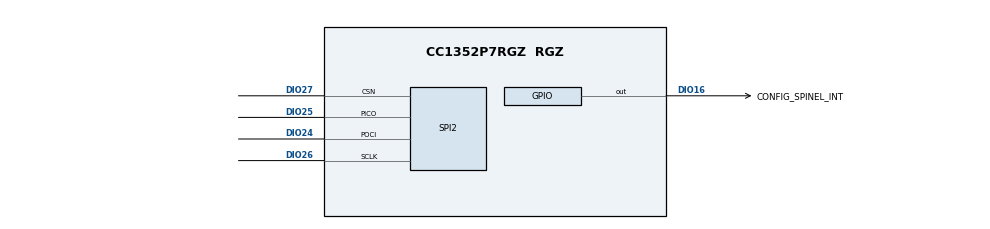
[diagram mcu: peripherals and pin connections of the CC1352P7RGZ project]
/*
 * Copyright (c) 2018, Texas Instruments Incorporated
 * All rights reserved.
 *
 * Redistribution and use in source and binary forms, with or without
 * modification, are permitted provided that the following conditions
 * are met:
 *
 * *  Redistributions of source code must retain the above copyright
 *    notice, this list of conditions and the following disclaimer.
 *
 * *  Redistributions in binary form must reproduce the above copyright
 *    notice, this list of conditions and the following disclaimer in the
 *    documentation and/or other materials provided with the distribution.
 *
 * *  Neither the name of Texas Instruments Incorporated nor the names of
 *    its contributors may be used to endorse or promote products derived
 *    from this software without specific prior written permission.
 *
 * THIS SOFTWARE IS PROVIDED BY THE COPYRIGHT HOLDERS AND CONTRIBUTORS "AS IS"
 * AND ANY EXPRESS OR IMPLIED WARRANTIES, INCLUDING, BUT NOT LIMITED TO,
 * THE IMPLIED WARRANTIES OF MERCHANTABILITY AND FITNESS FOR A PARTICULAR
 * PURPOSE ARE DISCLAIMED. IN NO EVENT SHALL THE COPYRIGHT OWNER OR
 * CONTRIBUTORS BE LIABLE FOR ANY DIRECT, INDIRECT, INCIDENTAL, SPECIAL,
 * EXEMPLARY, OR CONSEQUENTIAL DAMAGES (INCLUDING, BUT NOT LIMITED TO,
 * PROCUREMENT OF SUBSTITUTE GOODS OR SERVICES; LOSS OF USE, DATA, OR PROFITS;
 * OR BUSINESS INTERRUPTION) HOWEVER CAUSED AND ON ANY THEORY OF LIABILITY,
 * WHETHER IN CONTRACT, STRICT LIABILITY, OR TORT (INCLUDING NEGLIGENCE OR
 * OTHERWISE) ARISING IN ANY WAY OUT OF THE USE OF THIS SOFTWARE,
 * EVEN IF ADVISED OF THE POSSIBILITY OF SUCH DAMAGE.
 */

/*
 *  cli_ftd.syscfg
 */

/**
 * @cliArgs --board "/ti/boards/LP_CC1352P7_4" --device "CC1352P7RGZ" --part "Default" --package "RGZ" --rtos "freertos" --product "simplelink_cc13xx_cc26xx_sdk@7.40.00.77"
 * @versions {"tool":"1.24.1+4189"}
 */

/* Modules */
var AESECB    = scripting.addModule("/ti/drivers/AESECB");
var DMA       = scripting.addModule("/ti/drivers/DMA");
var Device    = scripting.addModule("/ti/devices/CCFG");
var ECDH      = scripting.addModule("/ti/drivers/ECDH");
var ECDSA     = scripting.addModule("/ti/drivers/ECDSA");
var ECJPAKE   = scripting.addModule("/ti/drivers/ECJPAKE");
var GPIO      = scripting.addModule("/ti/drivers/GPIO");
var NVS       = scripting.addModule("/ti/drivers/NVS");
var Power     = scripting.addModule("/ti/drivers/Power");
var RF        = scripting.addModule("/ti/drivers/RF");
var RFCustom  = scripting.addModule("/ti/devices/radioconfig/custom");
var RFDesign  = scripting.addModule("/ti/devices/radioconfig/rfdesign");
var SHA2      = scripting.addModule("/ti/drivers/SHA2");
var CCFG      = scripting.addModule("/ti/devices/CCFG");
var SPI       = scripting.addModule("/ti/drivers/SPI");
var TRNG      = scripting.addModule("/ti/drivers/TRNG");
var UART2     = scripting.addModule("/ti/drivers/UART2");
var Watchdog  = scripting.addModule("/ti/drivers/Watchdog");


/* Instances */
var AESECB     = AESECB.addInstance();
var ECDH       = ECDH.addInstance();
var ECDSA      = ECDSA.addInstance();
var ECJPAKE    = ECJPAKE.addInstance();
var GPIO1      = GPIO.addInstance();
var GPIO2      = GPIO.addInstance();
var GPIO3      = GPIO.addInstance();
var GPIO4      = GPIO.addInstance();
var GPIO5      = GPIO.addInstance();
var NVS1       = NVS.addInstance();
var NVSDGB     = NVS.addInstance();
var SHA21      = SHA2.addInstance();
var SPI2       = SPI.addInstance();
var TRNG1      = TRNG.addInstance();
var UART2      = UART2.addInstance();
var Watchdog1  = Watchdog.addInstance();

const deviceId = system.deviceData.deviceId;


/* CCFG */
const ccfgSettings = system.getScript("/ti/common/lprf_ccfg_settings.js").ccfgSettings;
for(var setting in ccfgSettings)
{
    Device[setting] = ccfgSettings[setting];
}

/**
 * Write custom configuration values to the imported modules.
 */
CCFG.enableBootloader         = true;
CCFG.enableBootloaderBackdoor = true;
CCFG.dioBootloaderBackdoor    = 14;
CCFG.levelBootloaderBackdoor  = "Active low";
// CCFG.forceVddr                = true;
CCFG.ccfgTemplate.$name       = "ti_devices_CCFG_CCFGCC26XXTemplate0";

RFDesign.rfDesign = "LP_CC1352P7-4";
RFDesign.fbSub1g  = "none";
RFDesign.fb24g  = "fb2400";

RF.pinSelectionAntenna                      = 1;
RF.rfAntennaPinSymbol0                      = "CONFIG_RF_HIGH_PA";
RF.globalEventMask                          = ["RF_GlobalEventRadioPowerDown","RF_GlobalEventRadioSetup"];
RF.rfAntennaPin0.$assign                    = "DIO_28";
RF.rfAntennaPin0Instance.initialOutputState = scripting.forceWrite("Low");


/* UART */
UART2.$hardware                   = system.deviceData.board.components.XDS110UART;
UART2.$name                       = "CONFIG_UART2_0";

/* GPIO */
GPIO1.$hardware                   = system.deviceData.board.components["BTN-1"];
GPIO1.$name                       = "CONFIG_GPIO_BTN1";

GPIO2.$hardware                   = system.deviceData.board.components["BTN-2"];
GPIO2.$name                       = "CONFIG_GPIO_BTN2";

GPIO3.$hardware                   = system.deviceData.board.components.LED_GREEN;
GPIO3.$name                       = "CONFIG_GPIO_GLED";

GPIO4.$hardware                   = system.deviceData.board.components.LED_RED;
GPIO4.$name                       = "CONFIG_GPIO_RLED";


/* SPI for NCP */
SPI2.$name                   = "CONFIG_SPI_1";
SPI2.mode                    = "Four Pin SS Active Low";
SPI2.spi.pociPin.$assign     = "DIO24"
SPI2.spi.picoPin.$assign     = "DIO25"
SPI2.spi.sclkPin.$assign     = "DIO26"
SPI2.spi.csnPin.$assign      = "DIO27"

GPIO5.$name                  = "CONFIG_SPINEL_INT";
GPIO5.mode                   = "Output";
GPIO5.outputStrength         = "High";
GPIO5.initialOutputState     = "High";
GPIO5.gpioPin.$assign        = "DIO16";


/* NVS */
NVS1.$name = "CONFIG_NVSINTERNAL";
NVSDGB.$name = "CONFIG_NVS_DBG_INTERNAL";


/* place at the end of Flash */
if(deviceId.match(/CC((13|26).2(R|RB|P)7)/))
{
    NVS1.internalFlash.regionBase = 0xAA000;
    NVS1.internalFlash.regionSize = 0x4000;
    NVSDGB.internalFlash.regionBase = 0xA8000;
    NVSDGB.internalFlash.regionSize = 0x2000;
}
else
{
    throw new Error("Could not set NVS location for deviceId: " + deviceId);
}


/* Watchdog */
Watchdog1.$name             = "CONFIG_WATCHDOG0";
Watchdog1.period            = 1000;
Watchdog1.watchdog.$assign  = "WDT0";

/* TRNG */
TRNG1.$name  = "CONFIG_TRNG_THREAD";

/* AES */
AESECB.$name = "CONFIG_AESECB_MBEDTLS";

/* RF */

/* if an antenna component exists, assign it to the rf instance */
if (system.deviceData.board && system.deviceData.board.components.RF) {
    RF.$hardware = system.deviceData.board.components.RF;
}

const rfDesignSettings = system.getScript("/ti/common/lprf_rf_design_settings.js").rfDesignSettings;
for(var setting in rfDesignSettings)
{
    RFDesign[setting] = rfDesignSettings[setting];
}

/* Handling for RF frontend characterization */
if(deviceId.match(/CC((13|26).2(R|RB|P)7)/))
{
    RFCustom.ieee = ["ieee154"];
    var rfCodeExportConfig = RFCustom.radioConfigieee154.codeExportConfig
    RFCustom.radioConfigieee154.highPA = true;
    RFCustom.radioConfigieee154.txPowerHi = "10";
    RFCustom.radioConfigieee154.codeExportConfig.txPower = "20";
}
else
{
    throw new Error("Could not set RF frontend characterization for deviceId: " + deviceId);
}

var cmdList = [
    "cmdIeeeTx",
    "cmdIeeeRx",
    "cmdIeeeCsma",
    "cmdIeeeEdScan",
    "cmdIeeeRxAck",
    "cmdTxTest",
    "cmdRxTest",
];
rfCodeExportConfig.useConst     = true;
rfCodeExportConfig.useMulti     = false;
rfCodeExportConfig.symGenMethod = "Custom";

// Add high PA options
if(deviceId.match(/CC(265[12]P|2674P|1352P)/))
{
    cmdList.push("cmdRadioSetupPa");
    rfCodeExportConfig.cmdRadioSetupPa = "RF_cmdIeeeRadioSetup";
    rfCodeExportConfig.paExport = "combined";
}
else
{
    throw new Error("Could not add high PA options deviceId: " + deviceId);
}

rfCodeExportConfig.cmdList_ieee_15_4 = cmdList;
